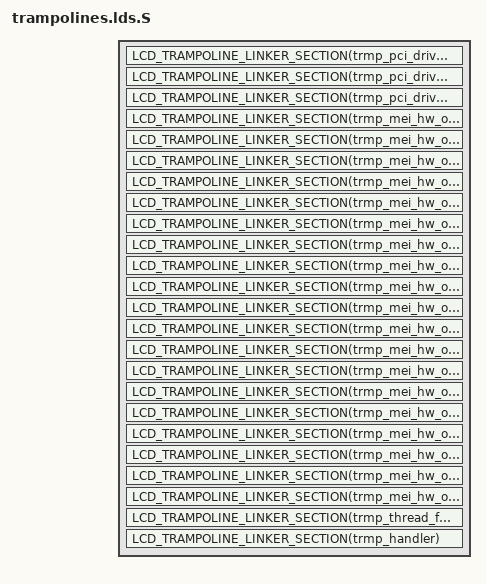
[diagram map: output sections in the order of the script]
#include <liblcd/trampoline_link.h>

SECTIONS{
	LCD_TRAMPOLINE_LINKER_SECTION(trmp_pci_driver_probe)
	LCD_TRAMPOLINE_LINKER_SECTION(trmp_pci_driver_remove)
	LCD_TRAMPOLINE_LINKER_SECTION(trmp_pci_driver_shutdown)
	LCD_TRAMPOLINE_LINKER_SECTION(trmp_mei_hw_ops_host_is_ready)
	LCD_TRAMPOLINE_LINKER_SECTION(trmp_mei_hw_ops_hw_is_ready)
	LCD_TRAMPOLINE_LINKER_SECTION(trmp_mei_hw_ops_hw_reset)
	LCD_TRAMPOLINE_LINKER_SECTION(trmp_mei_hw_ops_hw_start)
	LCD_TRAMPOLINE_LINKER_SECTION(trmp_mei_hw_ops_hw_config)
	LCD_TRAMPOLINE_LINKER_SECTION(trmp_mei_hw_ops_fw_status)
	LCD_TRAMPOLINE_LINKER_SECTION(trmp_mei_hw_ops_pg_state)
	LCD_TRAMPOLINE_LINKER_SECTION(trmp_mei_hw_ops_pg_in_transition)
	LCD_TRAMPOLINE_LINKER_SECTION(trmp_mei_hw_ops_pg_is_enabled)
	LCD_TRAMPOLINE_LINKER_SECTION(trmp_mei_hw_ops_intr_clear)
	LCD_TRAMPOLINE_LINKER_SECTION(trmp_mei_hw_ops_intr_enable)
	LCD_TRAMPOLINE_LINKER_SECTION(trmp_mei_hw_ops_intr_disable)
	LCD_TRAMPOLINE_LINKER_SECTION(trmp_mei_hw_ops_hbuf_free_slots)
	LCD_TRAMPOLINE_LINKER_SECTION(trmp_mei_hw_ops_hbuf_is_ready)
	LCD_TRAMPOLINE_LINKER_SECTION(trmp_mei_hw_ops_hbuf_max_len)
	LCD_TRAMPOLINE_LINKER_SECTION(trmp_mei_hw_ops_write)
	LCD_TRAMPOLINE_LINKER_SECTION(trmp_mei_hw_ops_rdbuf_full_slots)
	LCD_TRAMPOLINE_LINKER_SECTION(trmp_mei_hw_ops_read_hdr)
	LCD_TRAMPOLINE_LINKER_SECTION(trmp_mei_hw_ops_read)
	LCD_TRAMPOLINE_LINKER_SECTION(trmp_thread_fn)
	LCD_TRAMPOLINE_LINKER_SECTION(trmp_handler)
}

INSERT AFTER .text
